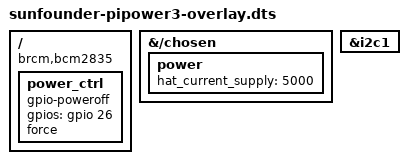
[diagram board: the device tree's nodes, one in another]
/dts-v1/;
/plugin/;

/ {
	compatible = "brcm,bcm2835";

	fragment@0 {
		target-path = "/chosen";
		__overlay__ {
			power: power {
				hat_current_supply = <5000>;
			};
		};
	};
	fragment@1 {
		target = <&i2c1>;
		__overlay__ {
			status = "okay";
		};
	};
	fragment@2 {
		target-path = "/";
		__overlay__ {
			power_ctrl: power_ctrl {
				compatible = "gpio-poweroff";
				gpios = <&gpio 26 0>;
				force;
			};
		};
	};
	__overrides__ {
		poweroff_pin =	<&power_ctrl>,"gpios:4";
	};
};
